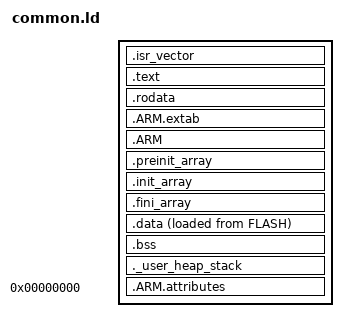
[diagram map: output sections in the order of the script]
/* Entry Point */
ENTRY(Reset_Handler)

_Min_Heap_Size = 0x200; /* Heap */
_Min_Stack_Size = 0x4000; /* Stack */

HEAP_SIZE   = DEFINED(__heap_size__)  ? __heap_size__   : _Min_Heap_Size;
STACK_SIZE  = DEFINED(__stack_size__) ? __stack_size__  : _Min_Stack_Size;

/* Initialize stack on end of memory */
_estack = ORIGIN(RAM) + LENGTH(RAM);
/* Generate a link error if heap and stack don't fit into RAM */
_stack_limit = _estack - STACK_SIZE;
ASSERT(_stack_limit >= _heap_limit, "RAM overflowed with stack and heap");

/* Noinit variables */
_board_dfu_dbl_tap    = ORIGIN(NOINIT);       /* quick boot, dfu & app erase  */
_board_tmp_boot_addr  = ORIGIN(NOINIT) + 4;   /* this boot address is used    */
_board_tmp_boot_magic = ORIGIN(NOINIT) + 8;   /* if this is set to deadbeef   */

/* Define output sections */
SECTIONS
{
  /* The startup code goes first into FLASH */
  .isr_vector :
  {
    . = ALIGN(4);
    KEEP(*(.isr_vector)) /* Startup code */
    . = ALIGN(4);
  } >FLASH

  /* The program code and other data goes into FLASH */
  .text :
  {
    . = ALIGN(4);
    *(.text)           /* .text sections (code) */
    *(.text*)          /* .text* sections (code) */
    *(.glue_7)         /* glue arm to thumb code */
    *(.glue_7t)        /* glue thumb to arm code */
    *(.eh_frame)

    KEEP (*(.init))
    KEEP (*(.fini))

    . = ALIGN(4);
    _etext = .;        /* define a global symbols at end of code */
  } >FLASH

  /* Constant data goes into FLASH */
  .rodata :
  {
    . = ALIGN(4);
    *(.rodata)         /* .rodata sections (constants, strings, etc.) */
    *(.rodata*)        /* .rodata* sections (constants, strings, etc.) */
    . = ALIGN(4);
  } >FLASH

  .ARM.extab   : { *(.ARM.extab* .gnu.linkonce.armextab.*) } >FLASH
  .ARM : {
    __exidx_start = .;
    *(.ARM.exidx*)
    __exidx_end = .;
  } >FLASH

  .preinit_array     :
  {
    PROVIDE_HIDDEN (__preinit_array_start = .);
    KEEP (*(.preinit_array*))
    PROVIDE_HIDDEN (__preinit_array_end = .);
  } >FLASH

  .init_array :
  {
    PROVIDE_HIDDEN (__init_array_start = .);
    KEEP (*(SORT(.init_array.*)))
    KEEP (*(.init_array*))
    PROVIDE_HIDDEN (__init_array_end = .);
  } >FLASH

  .fini_array :
  {
    PROVIDE_HIDDEN (__fini_array_start = .);
    KEEP (*(SORT(.fini_array.*)))
    KEEP (*(.fini_array*))
    PROVIDE_HIDDEN (__fini_array_end = .);
  } >FLASH

  /* used by the startup to initialize data */
  _sidata = LOADADDR(.data);

  /* Initialized data sections goes into RAM, load LMA copy after code */
  .data :
  {
    . = ALIGN(4);
    _sdata = .;        /* create a global symbol at data start */
    *(.data)           /* .data sections */
    *(.data*)          /* .data* sections */

    . = ALIGN(4);
    _edata = .;        /* define a global symbol at data end */
  } >RAM AT> FLASH


  /* Uninitialized data section */
  . = ALIGN(4);
  .bss :
  {
    /* This is used by the startup in order to initialize the .bss section */
    _sbss = .;         /* define a global symbol at bss start */
    __bss_start__ = _sbss;
    *(.bss)
    *(.bss*)
    *(COMMON)

    . = ALIGN(4);
    _ebss = .;         /* define a global symbol at bss end */
    __bss_end__ = _ebss;
  } >RAM

  /* User_heap_stack section, used to check that there is enough RAM left */
  ._user_heap_stack :
  {
    . = ALIGN(8);
    PROVIDE ( end = . );
    PROVIDE ( _end = . );
    . = . + HEAP_SIZE;
    _heap_limit = .;
    . = . + STACK_SIZE;
    . = ALIGN(8);
  } >RAM

  /* Remove information from the standard libraries */
  /DISCARD/ :
  {
    libc.a ( * )
    libm.a ( * )
    libgcc.a ( * )
  }

  .ARM.attributes 0 : { *(.ARM.attributes) }
}
